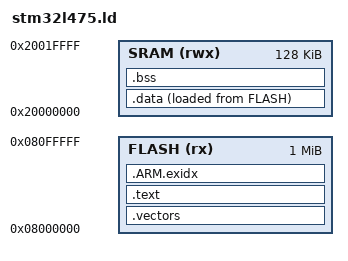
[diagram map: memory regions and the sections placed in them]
/* Linker script for STM32L475VG (b-l475e-iot01a, QEMU) — Cortex-M4 */
MEMORY
{
    FLASH (rx)  : ORIGIN = 0x08000000, LENGTH = 1M
    SRAM  (rwx) : ORIGIN = 0x20000000, LENGTH = 128K
}

ENTRY(Reset_Handler)

SECTIONS
{
    .vectors : {
        KEEP(*(.vectors))
    } > FLASH

    .text : {
        *(.text*)
        *(.rodata*)
    } > FLASH

    .ARM.exidx : {
        *(.ARM.exidx*)
    } > FLASH

    .data : {
        _sdata = .;
        *(.data*)
        _edata = .;
    } > SRAM AT > FLASH

    .bss : {
        _sbss = .;
        *(.bss*)
        *(COMMON)
        _ebss = .;
    } > SRAM

    _estack = ORIGIN(SRAM) + LENGTH(SRAM);
}
